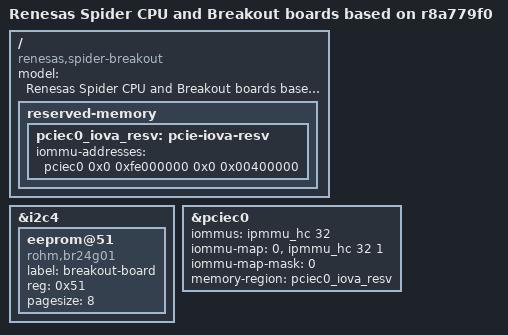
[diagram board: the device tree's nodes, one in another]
// SPDX-License-Identifier: (GPL-2.0 OR MIT)
/*
 * Device Tree Source for the Spider CPU and BreakOut boards
 * (PCIe RC mode with remote DW PCIe eDMA used for NTB transport)
 *
 * Based on the base r8a779f0-spider.dts.
 *
 * Copyright (C) 2025 Renesas Electronics Corp.
 */

/dts-v1/;
#include "r8a779f0-spider-cpu.dtsi"
#include "r8a779f0-spider-ethernet.dtsi"

/ {
	model = "Renesas Spider CPU and Breakout boards based on r8a779f0";
	compatible = "renesas,spider-breakout", "renesas,spider-cpu",
		     "renesas,r8a779f0";

	reserved-memory {
		#address-cells = <2>;
		#size-cells = <2>;
		ranges;

		/*
		 * Reserve 4 MiB of IOVA starting at 0xfe000000. Allowing DMA
		 * writes whose DAR (destination IOVA) falls numerically inside
		 * the ECAM/config window has been observed to trigger
		 * controller misbehavior.
		 */
		pciec0_iova_resv: pcie-iova-resv {
			iommu-addresses = <&pciec0 0x0 0xfe000000 0x0 0x00400000>;
		};
	};
};

&i2c4 {
	eeprom@51 {
		compatible = "rohm,br24g01", "atmel,24c01";
		label = "breakout-board";
		reg = <0x51>;
		pagesize = <8>;
	};
};

&pciec0 {
	iommus = <&ipmmu_hc 32>;
	iommu-map = <0 &ipmmu_hc 32 1>;
	iommu-map-mask = <0>;

	memory-region = <&pciec0_iova_resv>;
};
